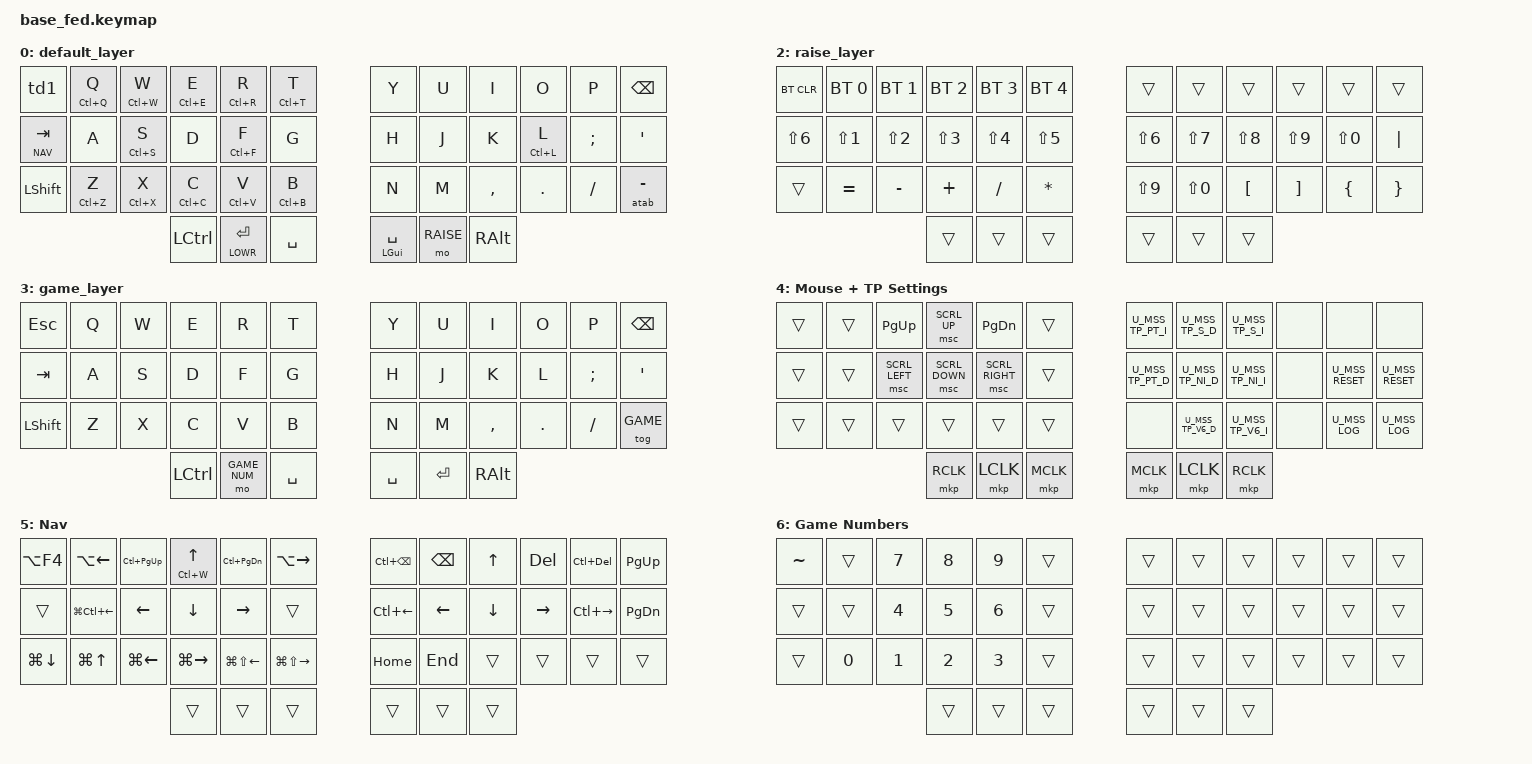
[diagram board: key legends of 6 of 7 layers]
/*
 * Copyright (c) 2020 The ZMK Contributors
 *
 * SPDX-License-Identifier: MIT
 */

// ===== LAYER DEFINITIONS =====
#define BASE         0
#define LOWR         1
#define RAISE        2
#define GAME         3
#define MOUSE_TP_SET 4
#define NAV          5
#define GAME_NUM     6

// ===== INCLUDES =====
#include <behaviors.dtsi>
#include <dt-bindings/zmk/keys.h>
#include <dt-bindings/zmk/bt.h>
#include <dt-bindings/zmk/outputs.h>
#include <dt-bindings/zmk/rgb.h>
#include <dt-bindings/zmk/ext_power.h>

#include "includes/mouse_keys.dtsi"
#include "includes/mouse_tp.dtsi"
#include "includes/mouse_tp_badjeff_input_listener.dtsi"

// ===== BEHAVIOR MODIFICATIONS =====
&mt {
    tapping-term-ms = <300>;
};

&sl {
    release-after-ms = <2000>;
};

&lt {
    tapping-term-ms = <300>;
};

// ===== MACROS =====
/ {
    macros {
        pwr: pwr {
            label = "pwr";
            compatible = "zmk,behavior-macro";
            #binding-cells = <0>;
            wait-ms = <1000>;
            tap-ms = <40>;
            bindings = <&macro_tap &kp RG(X)>, <&macro_wait_time 80>, <&macro_tap &kp UP &kp UP &kp RIGHT &kp UP &kp UP &kp RET>;
        };

        sleep: sleep {
            label = "sleep";
            compatible = "zmk,behavior-macro";
            #binding-cells = <0>;
            wait-ms = <1000>;
            tap-ms = <40>;
            bindings = <&macro_tap &kp RG(X)>, <&macro_wait_time 80>, <&macro_tap &kp UP &kp UP &kp RIGHT &kp DOWN &kp RET>;
        };

        atab: atab {
            label = "atab";
            compatible = "zmk,behavior-macro";
            #binding-cells = <0>;
            wait-ms = <20>;
            tap-ms = <20>;
            bindings = <&macro_press &kp LALT &mo NAV>, <&macro_tap &kp TAB>, <&macro_pause_for_release>, <&macro_release &kp LALT &mo NAV>;
        };
    };
};

// ===== BEHAVIORS =====
/ {
    behaviors {
        // Tap dance behaviors
        td1: tap_dance_1 {
            compatible = "zmk,behavior-tap-dance";
            label = "TAP_DANCE_1";
            #binding-cells = <0>;
            tapping-term-ms = <300>;
            bindings = <&kp ESC>, <&kp DEL>;
        };


        // Hold-tap behaviors
        ht_tp: holdTap_tapPreferred {
            compatible = "zmk,behavior-hold-tap";
            label = "ht_tp";
            #binding-cells = <2>;
            tapping-term-ms = <300>;
            quick-tap-ms = <300>;
            require-prior-idle-ms = <250>;
            flavor = "tap-preferred";
            bindings = <&kp>, <&kp>;
        };

        ht_gui_space: ht_gui_space {
            compatible = "zmk,behavior-hold-tap";
            label = "ht_gui_space";
            #binding-cells = <2>;
            tapping-term-ms = <300>;
            quick-tap-ms = <200>;
            require-prior-idle-ms = <200>;
            flavor = "balanced";
            bindings = <&kp>, <&kp>;
        };

        ht_atab: holdTap_aTab {
            compatible = "zmk,behavior-hold-tap";
            label = "ht_atab";
            #binding-cells = <2>;
            tapping-term-ms = <300>;
            quick-tap-ms = <300>;
            require-prior-idle-ms = <400>;
            flavor = "tap-preferred";
            bindings = <&atab>, <&kp>;
        };

        /*
         * Layer Toggle
         *
         * Usage: &ltog LGUI NAV
         * Tap: Layer Toggle
         * Hold: Keypress
         */
        ltog: ltog {
            compatible = "zmk,behavior-hold-tap";
            #binding-cells = <2>;
            flavor = "tap-preferred";
            tapping-term-ms = <300>;
            bindings = <&kp>, <&tog>;
        };

        /*
         * Layer & mouse key
         *
         * Usage: &lt_mkp NUM RCLK
         * Tap: Mouse RCLK
         * Hold: Layer NUM
         */
        lt_mkp: lt_mkp {
            compatible = "zmk,behavior-hold-tap";
            #binding-cells = <2>;
            flavor = "tap-preferred";
            tapping-term-ms = <300>;
            bindings = <&mo>, <&mkp>;
        };

        /*
         * GUI Hold-Tap
         *
         * Usage: &ht_gui 0 0
         * Tap: GUI key press
         * Hold: GUI key hold
         */
        ht_gui: ht_gui {
            compatible = "zmk,behavior-hold-tap";
            #binding-cells = <2>;
            flavor = "tap-preferred";
            tapping-term-ms = <300>;
            bindings = <&kp>, <&kp>;
        };

        ht_grave_tilde: ht_grave_tilde {
            compatible = "zmk,behavior-hold-tap";
            #binding-cells = <2>;
            flavor = "tap-preferred";
            tapping-term-ms = <300>;
            bindings = <&kp>, <&kp>;
        };
    };
};

// ===== CONDITIONAL LAYERS =====
// Disabled to allow trackpoint layer-toggle to work without conflicts
// / {
//     conditional_layers {
//         compatible = "zmk,conditional-layers";
//         dual_hold_layer {
//             if-layers = <LOWR RAISE>;
//             then-layer = <MOUSE_TP_SET>;
//         };
//     };
// };

// ===== CAPS WORD CONFIGURATION =====
&caps_word {
    continue-list = <UNDERSCORE MINUS>;
};
// ===== KEYMAP =====
/ {
    keymap {
        compatible = "zmk,keymap";

        default_layer {
            // ┌─────┬─────┬─────┬─────┬─────┬─────┐   ┌─────┬─────┬─────┬─────┬─────┬─────┐
            // │ td1 │  Q  │  W  │  E  │  R  │  T  │   │  Y  │  U  │  I  │  O  │  P  │BKSP │
            // ├─────┼─────┼─────┼─────┼─────┼─────┤   ├─────┼─────┼─────┼─────┼─────┼─────┤
            // │aTAB │  A  │  S  │  D  │  F  │  G  │   │  H  │  J  │  K  │  L  │  ;  │  '  │
            // ├─────┼─────┼─────┼─────┼─────┼─────┤   ├─────┼─────┼─────┼─────┼─────┼─────┤
            // │SHFT │  Z  │  X  │  C  │  V  │  B  │   │  N  │  M  │  ,  │  .  │  /  │  -  │
            // └─────┴─────┴─────┼─────┼─────┼─────┤   ├─────┼─────┼─────┼─────┴─────┴─────┘
            //                   │ CTL │ LWR │ SPC │   │ GUI │ RSE │ ALT │
            //                   └─────┴─────┴─────┘   └─────┴─────┴─────┘
            bindings = <
                &td1          &ht_tp LC(Q) Q       &ht_tp LC(W) W      &ht_tp LC(E) E    &ht_tp LC(R) R      &ht_tp LC(T) T           &kp Y      &kp U          &kp I      &kp O    &kp P     &kp BSPC
                &lt NAV TAB &kp A      &ht_tp LC(S) S       &kp D       &ht_tp LC(F) F              &kp G                 &kp H      &kp J    &kp K   &ht_tp LC(L) L     &kp SEMI  &kp SQT
                &kp LSHFT     &ht_tp LC(Z) Z   &ht_tp LC(X) X   &ht_tp LC(C) C   &ht_tp LC(V) V     &ht_tp LC(B) B        &kp N      &kp M          &kp COMMA  &kp DOT  &kp FSLH  &ht_atab 0 MINUS
                                                                &kp LCTRL        &lt LOWR RET       &kp SPACE         &ht_gui_space LGUI SPACE  &mo RAISE &kp RALT
            >;
        };

        lower_layer {
            // ┌─────┬─────┬─────┬─────┬─────┬─────┐   ┌─────┬─────┬─────┬─────┬─────┬─────┐
            // │  ~  │  *  │  7  │  8  │  9  │  +  │   │     │     │PrtSc│     │     │Game │
            // ├─────┼─────┼─────┼─────┼─────┼─────┤   ├─────┼─────┼─────┼─────┼─────┼─────┤
            // │atab │  /  │  4  │  5  │  6  │  -  │   │     │vDown│mute │ vUP │     │sleep│
            // ├─────┼─────┼─────┼─────┼─────┼─────┤   ├─────┼─────┼─────┼─────┼─────┼─────┤
            // │Bspc │  0  │  1  │  2  │  3  │ LNC │   │scrSh│prev │stop │next │  \  │ pwr │
            // └─────┴─────┴─────┼─────┼─────┼─────┤   ├─────┼─────┼─────┼─────┴─────┴─────┘
            //                   │  .  │     │     │   │     │     │     │
            //                   └─────┴─────┴─────┘   └─────┴─────┴─────┘
            bindings = <
                &ht_grave_tilde TILDE GRAVE     &kp STAR        &ht_tp F7 N7    &ht_tp F8 N8    &ht_tp F9 N9    &ht_tp F10 PLUS      &trans            &trans       &kp PSCRN     &trans        &trans        &tog GAME
                &ht_atab 0 TAB &kp FSLH        &ht_tp F4 N4    &ht_tp F5 N5    &ht_tp F6 N6    &ht_tp F11 MINUS     &kp LA(HOME)   &kp C_VOL_DN &kp C_MUTE    &kp C_VOL_UP  &trans        &sleep
                &kp BSPC   &kp N0          &ht_tp F1 N1    &ht_tp F2 N2    &ht_tp F3 N3    &ht_tp F12 LA(SPACE) &kp LC(RA(LS(H))) &kp C_PREV   &kp C_PP      &kp C_NEXT    &kp BSLH      &pwr
                                                            &kp DOT         &trans          &sk RGUI             &sk RGUI   &trans        &trans
            >;

        };



        raise_layer {
            // ┌─────┬─────┬─────┬─────┬─────┬─────┐   ┌─────┬─────┬─────┬─────┬─────┬─────┐
            // │BTCLR│ BT1 │ BT2 │ BT3 │ BT4 │ BT5 │   │     │     │     │     │     │     │
            // ├─────┼─────┼─────┼─────┼─────┼─────┤   ├─────┼─────┼─────┼─────┼─────┼─────┤
            // │  ^  │  !  │  @  │  #  │  $  │  %  │   │  ^  │  &  │  *  │  (  │  )  │  |  │
            // ├─────┼─────┼─────┼─────┼─────┼─────┤   ├─────┼─────┼─────┼─────┼─────┼─────┤
            // │     │  =  │  -  │  +  │  /  │  *  │   │  (  │  )  │  [  │  ]  │  {  │  }  │
            // └─────┴─────┴─────┼─────┼─────┼─────┤   ├─────┼─────┼─────┼─────┴─────┴─────┘
            //                   │     │     │     │   │     │     │     │
            //                   └─────┴─────┴─────┘   └─────┴─────┴─────┘
            bindings = <
                &bt BT_CLR &bt BT_SEL 0 &bt BT_SEL 1 &bt BT_SEL 2 &bt BT_SEL 3 &bt BT_SEL 4      &trans     &trans &trans &trans &trans &trans
                &kp LS(N6) &kp LS(N1)   &kp LS(N2)   &kp LS(N3)   &kp LS(N4)   &kp LS(N5)        &kp LS(N6) &kp LS(N7)   &kp LS(N8) &kp LS(N9) &kp LS(N0) &kp PIPE
                &trans     &kp EQUAL    &kp MINUS    &kp PLUS     &kp FSLH     &kp STAR          &kp LS(N9) &kp LS(N0)   &kp LBKT  &kp RBKT   &kp LBRC   &kp RBRC
                                                     &trans       &trans       &trans            &trans     &trans &trans
            >;
        };

        game_layer {
            // ┌─────┬─────┬─────┬─────┬─────┬─────┐   ┌─────┬─────┬─────┬─────┬─────┬─────┐
            // │ td1 │  Q  │  W  │  E  │  R  │  T  │   │  Y  │  U  │  I  │  O  │  P  │BKSP │
            // ├─────┼─────┼─────┼─────┼─────┼─────┤   ├─────┼─────┼─────┼─────┼─────┼─────┤
            // │ TAB │  A  │  S  │  D  │  F  │  G  │   │  H  │  J  │  K  │  L  │  ;  │  '  │
            // ├─────┼─────┼─────┼─────┼─────┼─────┤   ├─────┼─────┼─────┼─────┼─────┼─────┤
            // │SHFT │  Z  │  X  │  C  │  V  │  B  │   │  N  │  M  │  ,  │  .  │  /  │ ent │
            // └─────┴─────┴─────┼─────┼─────┼─────┤   ├─────┼─────┼─────┼─────┴─────┴─────┘
            //                   │ CTL │ LWR │ SPC │   │ SPC │ RSE │ ALT │
            //                   └─────┴─────┴─────┘   └─────┴─────┴─────┘
            bindings = <
                &kp ESC   &kp Q   &kp W     &kp E     &kp R      &kp T        &kp Y     &kp U     &kp I     &kp O   &kp P    &kp BSPC
                &kp TAB   &kp A   &kp S     &kp D     &kp F      &kp G        &kp H     &kp J     &kp K     &kp L   &kp SEMI &kp SQT
                &kp LSHFT &kp Z   &kp X     &kp C     &kp V      &kp B        &kp N     &kp M     &kp COMMA &kp DOT &kp FSLH &tog GAME
                                  &kp LCTRL &mo GAME_NUM &kp SPACE               &kp SPACE &kp RET &kp RALT
            >;
        };

        MOUSE_TP_SET_layer {
            display-name = "Mouse + TP Settings";
            // ┌─────┬─────┬─────┬─────┬─────┬─────┐   ┌─────┬─────┬─────┬─────┬─────┬─────┐
            // │     │     │PgUp │ SUp │PgDn │     │   │TPPTI│TP_SD│TP_SI│     │     │     │
            // ├─────┼─────┼─────┼─────┼─────┼─────┤   ├─────┼─────┼─────┼─────┼─────┼─────┤
            // │     │     │ SLt │ SDn │ SRt │     │   │TPPTD│TPNID│TPNII│     │RESET│RESET│
            // ├─────┼─────┼─────┼─────┼─────┼─────┤   ├─────┼─────┼─────┼─────┼─────┼─────┤
            // │     │     │     │     │     │     │   │     │TPV6D│TPV6I│     │ LOG │ LOG │
            // └─────┴─────┴─────┼─────┼─────┼─────┤   ├─────┼─────┼─────┼─────┴─────┴─────┘
            //                   │ RCK │ LCK │ MCK │   │ MCK │ LCK │ RCK │
            //                   └─────┴─────┴─────┘   └─────┴─────┴─────┘
            bindings = <
                &trans &trans           &kp PG_UP        &msc SCRL_UP   &kp PG_DN         &trans            U_MSS_TP_PT_I U_MSS_TP_S_D  U_MSS_TP_S_I  &none  &none       &none
                &trans &trans           &msc SCRL_LEFT   &msc SCRL_DOWN &msc SCRL_RIGHT   &trans            U_MSS_TP_PT_D U_MSS_TP_NI_D U_MSS_TP_NI_I &none  U_MSS_RESET U_MSS_RESET
                &trans &trans           &trans           &trans         &trans            &trans            &none         U_MSS_TP_V6_D U_MSS_TP_V6_I &none  U_MSS_LOG   U_MSS_LOG
                                                         &mkp RCLK      &mkp LCLK         &mkp MCLK         &mkp MCLK     &mkp LCLK     &mkp RCLK
            >;
        };

        nav_layer {
            display-name = "Nav";
            // ┌─────┬─────┬─────┬─────┬─────┬─────┐   ┌─────┬─────┬─────┬─────┬─────┬─────┐
            // │wCls │bBack│pTab │ Up  │nTab │bFwd │   │delWL│bspc │ up  │ del │delWR│PgUp │
            // ├─────┼─────┼─────┼─────┼─────┼─────┤   ├─────┼─────┼─────┼─────┼─────┼─────┤
            // │     │wslft│Left │Down │Right│     │   │wrdLf│left │down │right│wrdRt│PgDn │
            // ├─────┼─────┼─────┼─────┼─────┼─────┤   ├─────┼─────┼─────┼─────┼─────┼─────┤
            // │wDown│wUp  │wLeft│wRght│wnext│wprev│   │ Home│ End │     │     │     │     │
            // └─────┴─────┴─────┼─────┼─────┼─────┤   ├─────┼─────┼─────┼─────┴─────┴─────┘
            //                   │     │     │     │   │     │     │     │
            //                   └─────┴─────┴─────┘   └─────┴─────┴─────┘
            bindings = <
                &kp LA(F4)   &kp LA(LEFT)    &kp LC(PG_UP)   &ht_tp LC(W) UP     &kp LC(PG_DN)    &kp LA(RIGHT)   &kp LC(BSPC)  &kp BSPC      &kp UP    &kp DEL   &kp LC(DEL)   &kp PG_UP
                &trans       &kp LG(LC(LEFT)) &kp LEFT      &kp DOWN    &kp RIGHT        &trans           &kp LC(LEFT)  &kp LEFT      &kp DOWN  &kp RIGHT &kp LC(RIGHT)       &kp PG_DN
                &kp LG(DOWN) &kp LG(UP)       &kp LG(LEFT)  &kp LG(RIGHT) &kp LG(LS(LEFT)) &kp LG(LS(RIGHT))     &kp HOME   &kp END       &trans    &trans    &trans        &trans
                                                             &trans       &trans           &trans                &trans     &trans        &trans
            >;
        };

        game_num_layer {
            display-name = "Game Numbers";
            // ┌─────┬─────┬─────┬─────┬─────┬─────┐   ┌─────┬─────┬─────┬─────┬─────┬─────┐
            // │  ~  │     │  7  │  8  │  9  │     │   │     │     │     │     │     │     │
            // ├─────┼─────┼─────┼─────┼─────┼─────┤   ├─────┼─────┼─────┼─────┼─────┼─────┤
            // │     │     │  4  │  5  │  6  │     │   │     │     │     │     │     │     │
            // ├─────┼─────┼─────┼─────┼─────┼─────┤   ├─────┼─────┼─────┼─────┼─────┼─────┤
            // │     │  0  │  1  │  2  │  3  │     │   │     │     │     │     │     │     │
            // └─────┴─────┴─────┼─────┼─────┼─────┤   ├─────┼─────┼─────┼─────┴─────┴─────┘
            //                   │     │     │     │   │     │     │     │
            //                   └─────┴─────┴─────┘   └─────┴─────┴─────┘
            bindings = <
                &kp TILDE  &trans       &kp N7       &kp N8       &kp N9       &trans            &trans       &trans       &trans       &trans       &trans       &trans
                &trans     &trans       &kp N4       &kp N5       &kp N6       &trans            &trans       &trans       &trans       &trans       &trans       &trans
                &trans     &kp N0       &kp N1       &kp N2       &kp N3       &trans            &trans       &trans       &trans       &trans       &trans       &trans
                                                     &trans       &trans       &trans            &trans       &trans       &trans
            >;
        };
    };
};
